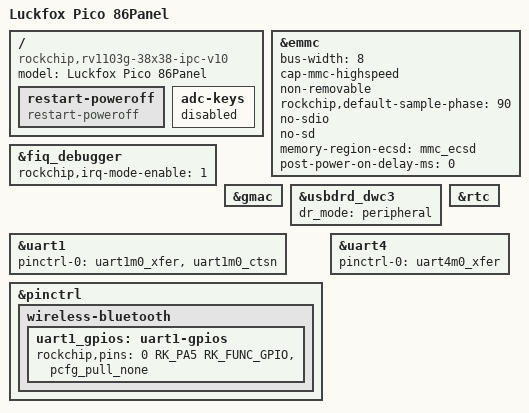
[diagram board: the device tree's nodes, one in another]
// SPDX-License-Identifier: (GPL-2.0+ OR MIT)
/*
 * Copyright (c) 2022 Rockchip Electronics Co., Ltd.
 */

/dts-v1/;
#include "rv1106.dtsi"
#include "rv1106-luckfox-pico-86panel-ipc.dtsi"
#include <dt-bindings/input/input.h>
#include <dt-bindings/display/media-bus-format.h>

/ {
	model = "Luckfox Pico 86Panel";
	compatible = "rockchip,rv1103g-38x38-ipc-v10", "rockchip,rv1106g3";

	restart-poweroff {
		compatible = "restart-poweroff";
	};

	adc-keys {
		status = "disabled";
	};
};

/**********CRU**********/
//&cru {
//	assigned-clocks =
//		<&cru PLL_GPLL>, <&cru PLL_CPLL>,
//		<&cru ARMCLK>,
//		<&cru ACLK_PERI_ROOT>, <&cru HCLK_PERI_ROOT>,
//		<&cru PCLK_PERI_ROOT>, <&cru ACLK_BUS_ROOT>,
//		<&cru PCLK_TOP_ROOT>, <&cru PCLK_PMU_ROOT>,
//		<&cru HCLK_PMU_ROOT>, <&cru CLK_500M_SRC>;
//	assigned-clock-rates =
//		<1188000000>, <700000000>,
//		<1104000000>,
//		<400000000>, <200000000>,
//		<100000000>, <300000000>,
//		<100000000>, <100000000>,
//		<200000000>, <700000000>;
//};

/**********NPU**********/
//&npu {
//	assigned-clock-rates = <700000000>;
//};

/**********EMMC**********/
&emmc {
	bus-width = <8>;
	cap-mmc-highspeed;
	non-removable;
	// mmc-hs200-1_8v;
	rockchip,default-sample-phase = <90>;
	no-sdio;
	no-sd;
	memory-region-ecsd = <&mmc_ecsd>;
	post-power-on-delay-ms = <0>;
	status = "okay";
};

&fiq_debugger {
	rockchip,irq-mode-enable = <1>;
	status = "okay";
};

/**********ETH**********/
&gmac {
	status = "okay";
};

/**********USB**********/
&usbdrd_dwc3 {
	status = "okay";
	dr_mode = "peripheral";
	//dr_mode = "host";
};

/**********RTC**********/
&rtc {
	status = "okay";
};

/**********BT**********/
&uart1 {
	status = "okay";
	pinctrl-names = "default";
	pinctrl-0 = <&uart1m0_xfer &uart1m0_ctsn>;
};

&pinctrl {
	wireless-bluetooth {
		uart1_gpios: uart1-gpios {
			rockchip,pins = <0 RK_PA5 RK_FUNC_GPIO &pcfg_pull_none>;
		};
	};
};

/**********RS485**********/
&uart4 {
	status = "okay";
	pinctrl-names = "default";
	pinctrl-0 = <&uart4m0_xfer>;
};
